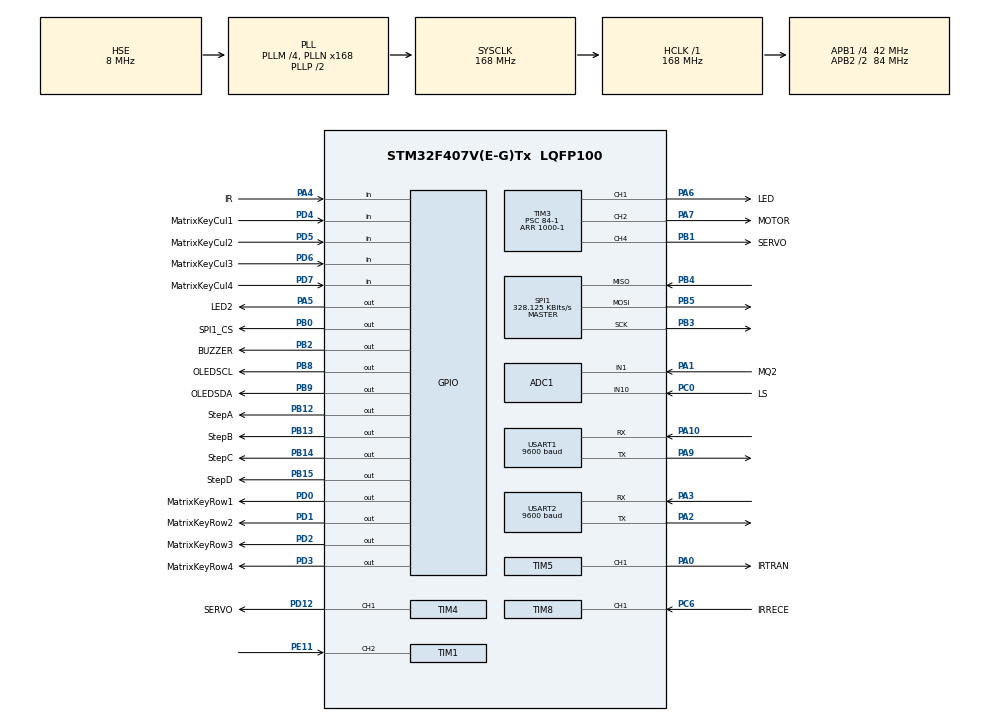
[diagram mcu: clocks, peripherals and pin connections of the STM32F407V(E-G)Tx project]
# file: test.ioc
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ADC1.Channel-0\#ChannelRegularConversion=ADC_CHANNEL_1
ADC1.Channel-1\#ChannelRegularConversion=ADC_CHANNEL_10
ADC1.ExternalTrigConv=ADC_EXTERNALTRIGCONV_T2_TRGO
ADC1.NbrOfConversion=2
ADC1.NbrOfConversionFlag=1
ADC1.Rank-0\#ChannelRegularConversion=1
ADC1.Rank-1\#ChannelRegularConversion=2
ADC1.SamplingTime-0\#ChannelRegularConversion=ADC_SAMPLETIME_3CYCLES
ADC1.SamplingTime-1\#ChannelRegularConversion=ADC_SAMPLETIME_3CYCLES
ADC1.master=1
Dma.Request0=TIM2_UP/CH3
Dma.Request1=USART1_RX
Dma.Request2=USART2_RX
Dma.TIM2_UP/CH3.0.Direction=DMA_PERIPH_TO_MEMORY
Dma.TIM2_UP/CH3.0.FIFOMode=DMA_FIFOMODE_DISABLE
Dma.TIM2_UP/CH3.0.Instance=DMA1_Stream1
Dma.TIM2_UP/CH3.0.MemDataAlignment=DMA_MDATAALIGN_WORD
Dma.TIM2_UP/CH3.0.MemInc=DMA_MINC_ENABLE
Dma.TIM2_UP/CH3.0.Mode=DMA_NORMAL
Dma.TIM2_UP/CH3.0.PeriphDataAlignment=DMA_PDATAALIGN_WORD
Dma.TIM2_UP/CH3.0.PeriphInc=DMA_PINC_DISABLE
Dma.TIM2_UP/CH3.0.Priority=DMA_PRIORITY_LOW
Dma.USART1_RX.1.Direction=DMA_PERIPH_TO_MEMORY
Dma.USART1_RX.1.FIFOMode=DMA_FIFOMODE_DISABLE
Dma.USART1_RX.1.Instance=DMA2_Stream2
Dma.USART1_RX.1.MemDataAlignment=DMA_MDATAALIGN_BYTE
Dma.USART1_RX.1.MemInc=DMA_MINC_ENABLE
Dma.USART1_RX.1.Mode=DMA_NORMAL
Dma.USART1_RX.1.PeriphDataAlignment=DMA_PDATAALIGN_BYTE
Dma.USART1_RX.1.PeriphInc=DMA_PINC_DISABLE
Dma.USART1_RX.1.Priority=DMA_PRIORITY_LOW
Dma.USART2_RX.2.Direction=DMA_PERIPH_TO_MEMORY
Dma.USART2_RX.2.FIFOMode=DMA_FIFOMODE_DISABLE
Dma.USART2_RX.2.Instance=DMA1_Stream5
Dma.USART2_RX.2.MemDataAlignment=DMA_MDATAALIGN_BYTE
Dma.USART2_RX.2.MemInc=DMA_MINC_ENABLE
Dma.USART2_RX.2.Mode=DMA_NORMAL
Dma.USART2_RX.2.PeriphDataAlignment=DMA_PDATAALIGN_BYTE
Dma.USART2_RX.2.PeriphInc=DMA_PINC_DISABLE
Dma.USART2_RX.2.Priority=DMA_PRIORITY_LOW
IWDG.Prescaler=IWDG_PRESCALER_64
IWDG.Reload=2499
Mcu.Family=STM32F4
Mcu.Name=STM32F407V(E-G)Tx
Mcu.Package=LQFP100
NVIC.DMA1_Stream1_IRQn=true\:0\:0\:false\:false\:true\:false\:true\:true
NVIC.DMA1_Stream5_IRQn=true\:0\:0\:false\:false\:true\:false\:true\:true
NVIC.DMA2_Stream2_IRQn=true\:0\:0\:false\:false\:true\:false\:true\:true
NVIC.PriorityGroup=NVIC_PRIORITYGROUP_4
NVIC.TIM2_IRQn=true\:0\:0\:false\:false\:true\:true\:true\:true
NVIC.TIM3_IRQn=true\:0\:0\:false\:false\:true\:true\:true\:true
NVIC.TIM8_CC_IRQn=true\:0\:0\:false\:false\:true\:true\:true\:true
NVIC.USART1_IRQn=true\:0\:0\:false\:false\:true\:true\:true\:true
NVIC.USART2_IRQn=true\:0\:0\:false\:false\:true\:true\:true\:true
PA0-WKUP.GPIO_Label=IRTRAN
PA0-WKUP.Signal=S_TIM5_CH1
PA1.GPIO_Label=MQ2
PA1.Signal=ADCx_IN1
PA10.Mode=Asynchronous
PA10.Signal=USART1_RX
PA13.Mode=Serial_Wire
PA13.Signal=SYS_JTMS-SWDIO
PA14.Mode=Serial_Wire
PA14.Signal=SYS_JTCK-SWCLK
PA2.Mode=Asynchronous
PA2.Signal=USART2_TX
PA3.Mode=Asynchronous
PA3.Signal=USART2_RX
PA4.GPIO_Label=IR
PA4.GPIO_PuPd=GPIO_PULLUP
PA4.Signal=GPIO_Input
PA5.GPIO_Label=LED2
PA5.GPIO_ModeDefaultOutputPP=GPIO_MODE_OUTPUT_PP
PA5.GPIO_PuPd=GPIO_PULLDOWN
PA5.GPIO_Speed=GPIO_SPEED_FREQ_MEDIUM
PA5.PinState=GPIO_PIN_RESET
PA5.Signal=GPIO_Output
PA6.GPIO_Label=LED
PA6.Signal=S_TIM3_CH1
PA7.GPIO_Label=MOTOR
PA7.Signal=S_TIM3_CH2
PA9.Mode=Asynchronous
PA9.Signal=USART1_TX
PB0.GPIO_Label=SPI1_CS
PB0.GPIO_PuPd=GPIO_PULLUP
PB0.GPIO_Speed=GPIO_SPEED_FREQ_HIGH
PB0.PinState=GPIO_PIN_SET
PB0.Signal=GPIO_Output
PB1.GPIO_Label=SERVO
PB1.Signal=S_TIM3_CH4
PB12.GPIO_Label=StepA
PB12.GPIO_Speed=GPIO_SPEED_FREQ_MEDIUM
PB12.Signal=GPIO_Output
PB13.GPIO_Label=StepB
PB13.GPIO_Speed=GPIO_SPEED_FREQ_MEDIUM
PB13.Signal=GPIO_Output
PB14.GPIO_Label=StepC 
PB14.GPIO_Speed=GPIO_SPEED_FREQ_MEDIUM
PB14.Signal=GPIO_Output
PB15.GPIO_Label=StepD
PB15.GPIO_Speed=GPIO_SPEED_FREQ_MEDIUM
PB15.Signal=GPIO_Output
PB2.GPIO_Label=BUZZER
PB2.GPIO_ModeDefaultOutputPP=GPIO_MODE_OUTPUT_PP
PB2.GPIO_Speed=GPIO_SPEED_FREQ_MEDIUM
PB2.PinState=GPIO_PIN_SET
PB2.Signal=GPIO_Output
PB3.Mode=Full_Duplex_Master
PB3.Signal=SPI1_SCK
PB4.Mode=Full_Duplex_Master
PB4.Signal=SPI1_MISO
PB5.Mode=Full_Duplex_Master
PB5.Signal=SPI1_MOSI
PB8.GPIO_Label=OLEDSCL
PB8.GPIO_ModeDefaultOutputPP=GPIO_MODE_OUTPUT_OD
PB8.GPIO_PuPd=GPIO_NOPULL
PB8.GPIO_Speed=GPIO_SPEED_FREQ_HIGH
PB8.Signal=GPIO_Output
PB9.GPIO_Label=OLEDSDA
PB9.GPIO_ModeDefaultOutputPP=GPIO_MODE_OUTPUT_OD
PB9.GPIO_PuPd=GPIO_NOPULL
PB9.GPIO_Speed=GPIO_SPEED_FREQ_HIGH
PB9.Signal=GPIO_Output
PC0.GPIO_Label=LS
PC0.Signal=ADCx_IN10
PC14-OSC32_IN.Mode=LSE-External-Oscillator
PC14-OSC32_IN.Signal=RCC_OSC32_IN
PC15-OSC32_OUT.Mode=LSE-External-Oscillator
PC15-OSC32_OUT.Signal=RCC_OSC32_OUT
PC6.GPIO_Label=IRRECE
PC6.Signal=S_TIM8_CH1
PD0.GPIO_Label=MatrixKeyRow1
PD0.GPIO_Speed=GPIO_SPEED_FREQ_MEDIUM
PD0.Signal=GPIO_Output
PD1.GPIO_Label=MatrixKeyRow2
PD1.GPIO_Speed=GPIO_SPEED_FREQ_MEDIUM
PD1.Signal=GPIO_Output
PD12.GPIO_Label=SERVO
PD12.Signal=S_TIM4_CH1
PD2.GPIO_Label=MatrixKeyRow3
PD2.GPIO_Speed=GPIO_SPEED_FREQ_MEDIUM
PD2.Signal=GPIO_Output
PD3.GPIO_Label=MatrixKeyRow4
PD3.GPIO_Speed=GPIO_SPEED_FREQ_MEDIUM
PD3.Signal=GPIO_Output
PD4.GPIO_Label=MatrixKeyCul1
PD4.GPIO_PuPd=GPIO_PULLUP
PD4.Signal=GPIO_Input
PD5.GPIO_Label=MatrixKeyCul2
PD5.GPIO_PuPd=GPIO_PULLUP
PD5.Signal=GPIO_Input
PD6.GPIO_Label=MatrixKeyCul3
PD6.GPIO_PuPd=GPIO_PULLUP
PD6.Signal=GPIO_Input
PD7.GPIO_Label=MatrixKeyCul4
PD7.GPIO_PuPd=GPIO_PULLUP
PD7.Signal=GPIO_Input
PE11.Signal=S_TIM1_CH2
PH0-OSC_IN.Mode=HSE-External-Oscillator
PH0-OSC_IN.Signal=RCC_OSC_IN
PH1-OSC_OUT.Mode=HSE-External-Oscillator
PH1-OSC_OUT.Signal=RCC_OSC_OUT
ProjectManager.HeapSize=0x200
ProjectManager.StackSize=0x400
ProjectManager.TargetToolchain=MDK-ARM V5.32
RCC.48MHZClocksFreq_Value=84000000
RCC.AHBFreq_Value=168000000
RCC.APB1CLKDivider=RCC_HCLK_DIV4
RCC.APB1Freq_Value=42000000
RCC.APB1TimFreq_Value=84000000
RCC.APB2CLKDivider=RCC_HCLK_DIV2
RCC.APB2Freq_Value=84000000
RCC.APB2TimFreq_Value=168000000
RCC.CortexFreq_Value=168000000
RCC.HCLKFreq_Value=168000000
RCC.HSE_VALUE=8000000
RCC.HSI_VALUE=16000000
RCC.PLLM=4
RCC.PLLN=168
RCC.PLLSourceVirtual=RCC_PLLSOURCE_HSE
RCC.RCC_RTC_Clock_Source=RCC_RTCCLKSOURCE_LSE
RCC.RCC_RTC_Clock_SourceVirtual=RCC_RTCCLKSOURCE_LSE
RCC.SYSCLKFreq_VALUE=168000000
RCC.SYSCLKSource=RCC_SYSCLKSOURCE_PLLCLK
RCC.VCOOutputFreq_Value=336000000
SH.ADCx_IN1.0=ADC1_IN1,IN1
SH.ADCx_IN10.0=ADC1_IN10,IN10
SH.S_TIM1_CH2.0=TIM1_CH2,Input_Capture2_from_TI2
SH.S_TIM3_CH1.0=TIM3_CH1,PWM Generation1 CH1
SH.S_TIM3_CH2.0=TIM3_CH2,PWM Generation2 CH2
SH.S_TIM3_CH4.0=TIM3_CH4,PWM Generation4 CH4
SH.S_TIM4_CH1.0=TIM4_CH1,PWM Generation1 CH1
SH.S_TIM5_CH1.0=TIM5_CH1,PWM Generation1 CH1
SH.S_TIM8_CH1.0=TIM8_CH1,Input_Capture1_from_TI1
SPI1.BaudRatePrescaler=SPI_BAUDRATEPRESCALER_256
SPI1.CLKPhase=SPI_PHASE_2EDGE
SPI1.CLKPolarity=SPI_POLARITY_HIGH
SPI1.CRCCalculation=SPI_CRCCALCULATION_DISABLE
SPI1.CalculateBaudRate=328.125 KBits/s
SPI1.Direction=SPI_DIRECTION_2LINES
SPI1.Mode=SPI_MODE_MASTER
SPI1.VirtualType=VM_MASTER
TIM1.Channel-Input_Capture2_from_TI2=TIM_CHANNEL_2
TIM2.AutoReloadPreload=TIM_AUTORELOAD_PRELOAD_DISABLE
TIM2.ClockDivision=TIM_CLOCKDIVISION_DIV1
TIM2.Period=20000-1
TIM2.Prescaler=8400-1
TIM2.TIM_MasterOutputTrigger=TIM_TRGO_UPDATE
TIM3.Channel-PWM\ Generation1\ CH1=TIM_CHANNEL_1
TIM3.Channel-PWM\ Generation2\ CH2=TIM_CHANNEL_2
TIM3.Channel-PWM\ Generation4\ CH4=TIM_CHANNEL_4
TIM3.OCMode_PWM-PWM\ Generation1\ CH1=TIM_OCMODE_PWM1
TIM3.Period=1000-1
TIM3.Prescaler=84-1
TIM4.Channel-PWM\ Generation1\ CH1=TIM_CHANNEL_1
TIM4.Period=20000-1
TIM4.Prescaler=84-1
TIM4.Pulse-PWM\ Generation1\ CH1=500
TIM5.Channel-PWM\ Generation1\ CH1=TIM_CHANNEL_1
TIM5.Period=2210-1
TIM5.Pulse-PWM\ Generation1\ CH1=768
TIM8.Channel-Input_Capture1_from_TI1=TIM_CHANNEL_1
TIM8.ICFilter_CH1=4
TIM8.ICPolarity_CH1=TIM_INPUTCHANNELPOLARITY_BOTHEDGE
TIM8.Prescaler=168-1
USART1.BaudRate=9600
USART1.VirtualMode=VM_ASYNC
USART2.BaudRate=9600
USART2.VirtualMode=VM_ASYNC
VP_IWDG_VS_IWDG.Mode=IWDG_Activate
VP_RTC_VS_RTC_Activate.Mode=RTC_Enabled
VP_RTC_VS_RTC_Calendar.Mode=RTC_Calendar
VP_TIM1_VS_ClockSourceINT.Mode=Internal
VP_TIM2_VS_ClockSourceINT.Mode=Internal
VP_TIM3_VS_ClockSourceINT.Mode=Internal
VP_TIM4_VS_ClockSourceINT.Mode=Internal
VP_TIM5_VS_ClockSourceINT.Mode=Internal
VP_TIM8_VS_ClockSourceINT.Mode=Internal
board=custom

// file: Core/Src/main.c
/* USER CODE BEGIN Header */
/**
  ******************************************************************************
  * @file           : main.c
  * @brief          : Main program body
  ******************************************************************************
  * @attention
  *
  * Copyright (c) 2026 STMicroelectronics.
  * All rights reserved.
  *
  * This software is licensed under terms that can be found in the LICENSE file
  * in the root directory of this software component.
  * If no LICENSE file comes with this software, it is provided AS-IS.
  *
  ******************************************************************************
  */
/* USER CODE END Header */
#include "main.h"
#include "adc.h"
#include "dma.h"
#include "iwdg.h"
#include "rtc.h"
#include "spi.h"
#include "tim.h"
#include "usart.h"
#include "gpio.h"

/* USER CODE BEGIN Includes */
#include "TaskDriver.h"
#include "SensorRead.h"
#include "OLED.h"
#include "Serial.h"
/* USER CODE END Includes */

void SystemClock_Config(void);

int main(void)
{

  /* MCU Configuration--------------------------------------------------------*/

  /* Reset of all peripherals, Initializes the Flash interface and the Systick. */
  HAL_Init();

  /* Configure the system clock */
  SystemClock_Config();

  /* Initialize all configured peripherals */
  MX_GPIO_Init();
  MX_DMA_Init();
  MX_TIM3_Init();
  MX_USART1_UART_Init();
  MX_TIM2_Init();
  MX_ADC1_Init();
  MX_USART2_UART_Init();
  MX_TIM4_Init();
  MX_SPI1_Init();
  MX_RTC_Init();
  MX_TIM5_Init();
  MX_TIM1_Init();
  MX_TIM8_Init();
  MX_IWDG_Init();
  /* USER CODE BEGIN 2 */
	SensorRead_Init();
	TaskDriver_Init();
//	OLED_Init();
  /* USER CODE END 2 */

  /* Infinite loop */
  /* USER CODE BEGIN WHILE */
  while (1)
  {
//		SensorRead_Run();
		TaskDriver_Run();
//		OLED_ShowHexNum(1, 1, Flash_ReadID(), 4);

    /* USER CODE END WHILE */

    /* USER CODE BEGIN 3 */
    //HAL_Delay(5000);
    HAL_IWDG_Refresh(&hiwdg);
  }
  /* USER CODE END 3 */
}

void SystemClock_Config(void)
{
  RCC_OscInitTypeDef RCC_OscInitStruct = {0};
  RCC_ClkInitTypeDef RCC_ClkInitStruct = {0};

  /** Configure the main internal regulator output voltage
  */
  __HAL_RCC_PWR_CLK_ENABLE();
  __HAL_PWR_VOLTAGESCALING_CONFIG(PWR_REGULATOR_VOLTAGE_SCALE1);

  /** Initializes the RCC Oscillators according to the specified parameters
  * in the RCC_OscInitTypeDef structure.
  */
  RCC_OscInitStruct.OscillatorType = RCC_OSCILLATORTYPE_LSI|RCC_OSCILLATORTYPE_HSE
                              |RCC_OSCILLATORTYPE_LSE;
  RCC_OscInitStruct.HSEState = RCC_HSE_ON;
  RCC_OscInitStruct.LSEState = RCC_LSE_ON;
  RCC_OscInitStruct.LSIState = RCC_LSI_ON;
  RCC_OscInitStruct.PLL.PLLState = RCC_PLL_ON;
  RCC_OscInitStruct.PLL.PLLSource = RCC_PLLSOURCE_HSE;
  RCC_OscInitStruct.PLL.PLLM = 4;
  RCC_OscInitStruct.PLL.PLLN = 168;
  RCC_OscInitStruct.PLL.PLLP = RCC_PLLP_DIV2;
  RCC_OscInitStruct.PLL.PLLQ = 4;
  if (HAL_RCC_OscConfig(&RCC_OscInitStruct) != HAL_OK)
  {
    Error_Handler();
  }

  /** Initializes the CPU, AHB and APB buses clocks
  */
  RCC_ClkInitStruct.ClockType = RCC_CLOCKTYPE_HCLK|RCC_CLOCKTYPE_SYSCLK
                              |RCC_CLOCKTYPE_PCLK1|RCC_CLOCKTYPE_PCLK2;
  RCC_ClkInitStruct.SYSCLKSource = RCC_SYSCLKSOURCE_PLLCLK;
  RCC_ClkInitStruct.AHBCLKDivider = RCC_SYSCLK_DIV1;
  RCC_ClkInitStruct.APB1CLKDivider = RCC_HCLK_DIV4;
  RCC_ClkInitStruct.APB2CLKDivider = RCC_HCLK_DIV2;

  if (HAL_RCC_ClockConfig(&RCC_ClkInitStruct, FLASH_LATENCY_5) != HAL_OK)
  {
    Error_Handler();
  }
}

void Error_Handler(void)
{
  __disable_irq();
  while (1)
  {
  }
}
